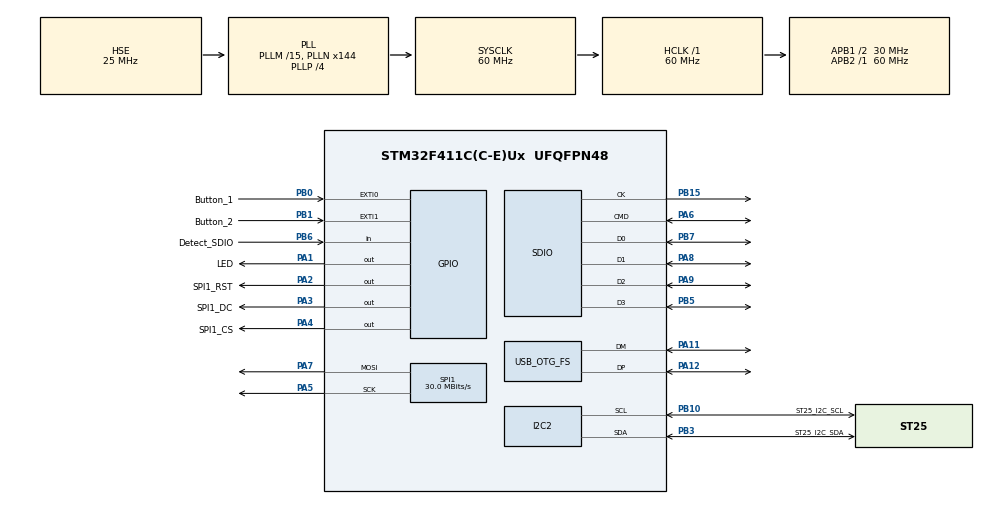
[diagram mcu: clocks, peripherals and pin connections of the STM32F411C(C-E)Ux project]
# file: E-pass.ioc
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FATFS.BSP.number=1
FATFS._CODE_PAGE=437
FATFS0.BSP.STBoard=false
FATFS0.BSP.api=Unknown
FATFS0.BSP.instance=PB6
FATFS0.BSP.ip=GPIO
FATFS0.BSP.mode=Input
FATFS0.BSP.name=Detect_SDIO
FATFS0.BSP.solution=PB6
Mcu.Family=STM32F4
Mcu.Name=STM32F411C(C-E)Ux
Mcu.Package=UFQFPN48
NVIC.EXTI0_IRQn=true\:0\:0\:false\:false\:true\:true\:true\:true
NVIC.EXTI1_IRQn=true\:0\:0\:false\:false\:true\:true\:true\:true
NVIC.OTG_FS_IRQn=true\:0\:0\:false\:false\:true\:false\:true\:true
NVIC.PriorityGroup=NVIC_PRIORITYGROUP_4
NVIC.SDIO_IRQn=true\:0\:0\:false\:false\:true\:true\:true\:true
PA1.GPIO_Label=LED
PA1.Signal=GPIO_Output
PA11.Mode=Device_Only
PA11.Signal=USB_OTG_FS_DM
PA12.Mode=Device_Only
PA12.Signal=USB_OTG_FS_DP
PA13.Mode=Serial_Wire
PA13.Signal=SYS_JTMS-SWDIO
PA14.Mode=Serial_Wire
PA14.Signal=SYS_JTCK-SWCLK
PA2.GPIO_Label=SPI1_RST
PA2.Signal=GPIO_Output
PA3.GPIO_Label=SPI1_DC
PA3.Signal=GPIO_Output
PA4.GPIO_Label=SPI1_CS
PA4.Signal=GPIO_Output
PA5.Mode=TX_Only_Simplex_Unidirect_Master
PA5.Signal=SPI1_SCK
PA6.Mode=SD_4_bits_Wide_bus
PA6.Signal=SDIO_CMD
PA7.Mode=TX_Only_Simplex_Unidirect_Master
PA7.Signal=SPI1_MOSI
PA8.Mode=SD_4_bits_Wide_bus
PA8.Signal=SDIO_D1
PA9.Mode=SD_4_bits_Wide_bus
PA9.Signal=SDIO_D2
PB0.GPIO_Label=Button_1
PB0.GPIO_ModeDefaultEXTI=GPIO_MODE_IT_FALLING
PB0.GPIO_PuPd=GPIO_PULLUP
PB0.Signal=GPXTI0
PB1.GPIO_Label=Button_2
PB1.GPIO_ModeDefaultEXTI=GPIO_MODE_IT_FALLING
PB1.GPIO_PuPd=GPIO_PULLUP
PB1.Signal=GPXTI1
PB10.GPIO_Label=ST25_I2C_SCL
PB10.Mode=I2C
PB10.Signal=I2C2_SCL
PB15.Mode=SD_4_bits_Wide_bus
PB15.Signal=SDIO_CK
PB3.GPIO_Label=ST25_I2C_SDA
PB3.Mode=I2C
PB3.Signal=I2C2_SDA
PB5.Mode=SD_4_bits_Wide_bus
PB5.Signal=SDIO_D3
PB6.GPIO_Label=Detect_SDIO
PB6.Signal=GPIO_Input
PB7.Mode=SD_4_bits_Wide_bus
PB7.Signal=SDIO_D0
PH0\ -\ OSC_IN.Mode=HSE-External-Oscillator
PH0\ -\ OSC_IN.Signal=RCC_OSC_IN
PH1\ -\ OSC_OUT.Mode=HSE-External-Oscillator
PH1\ -\ OSC_OUT.Signal=RCC_OSC_OUT
ProjectManager.HeapSize=0x200
ProjectManager.StackSize=0x400
ProjectManager.TargetToolchain=MDK-ARM V5.32
RCC.48MHZClocksFreq_Value=48000000
RCC.AHBFreq_Value=60000000
RCC.APB1CLKDivider=RCC_HCLK_DIV2
RCC.APB1Freq_Value=30000000
RCC.APB1TimFreq_Value=60000000
RCC.APB2Freq_Value=60000000
RCC.APB2TimFreq_Value=60000000
RCC.CortexFreq_Value=60000000
RCC.HCLKFreq_Value=60000000
RCC.HSE_VALUE=25000000
RCC.HSI_VALUE=16000000
RCC.LSE_VALUE=32768
RCC.PLLM=15
RCC.PLLN=144
RCC.PLLP=RCC_PLLP_DIV4
RCC.PLLQ=5
RCC.SYSCLKFreq_VALUE=60000000
RCC.SYSCLKSource=RCC_SYSCLKSOURCE_PLLCLK
RCC.VCOOutputFreq_Value=240000000
SDIO.ClockDiv=36
SPI1.CalculateBaudRate=30.0 MBits/s
SPI1.Direction=SPI_DIRECTION_2LINES
SPI1.Mode=SPI_MODE_MASTER
SPI1.VirtualType=VM_MASTER
USB_DEVICE.CLASS_NAME_FS=CDC
USB_DEVICE.VirtualMode=Cdc
USB_DEVICE.VirtualModeFS=Cdc_FS
USB_OTG_FS.VirtualMode=Device_Only
VP_FATFS_VS_SDIO.Mode=SDIO
VP_USB_DEVICE_VS_USB_DEVICE_CDC_FS.Mode=CDC_FS
board=custom

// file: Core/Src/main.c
/* USER CODE BEGIN Header */
/**
  ******************************************************************************
  * @file           : main.c
  * @brief          : Main program body
  ******************************************************************************
  * @attention
  *
  * Copyright (c) 2026 STMicroelectronics.
  * All rights reserved.
  *
  * This software is licensed under terms that can be found in the LICENSE file
  * in the root directory of this software component.
  * If no LICENSE file comes with this software, it is provided AS-IS.
  *
  ******************************************************************************
  */
/* USER CODE END Header */
#include "main.h"
#include "fatfs.h"
#include "i2c.h"
#include "sdio.h"
#include "spi.h"
#include "usb_device.h"
#include "gpio.h"

/* USER CODE BEGIN Includes */
#include "picture_transport.h"

/* USER CODE END Includes */

void SystemClock_Config(void);

int main(void)
{

  /* MCU Configuration--------------------------------------------------------*/

  /* Reset of all peripherals, Initializes the Flash interface and the Systick. */
  HAL_Init();

  /* Configure the system clock */
  SystemClock_Config();

  /* Initialize all configured peripherals */
  MX_GPIO_Init();
  MX_SDIO_SD_Init();
  MX_SPI1_Init();
  MX_USB_DEVICE_Init();
  MX_FATFS_Init();
  MX_I2C2_Init();
  /* USER CODE BEGIN 2 */
  PictureTransport_Init();

  /* USER CODE END 2 */

  /* Infinite loop */
  while (1)
  {

    /* USER CODE BEGIN 3 */
    PictureTransport_Task();

  }
  /* USER CODE END 3 */
}

void SystemClock_Config(void)
{
  RCC_OscInitTypeDef RCC_OscInitStruct = {0};
  RCC_ClkInitTypeDef RCC_ClkInitStruct = {0};

  /** Configure the main internal regulator output voltage
  */
  __HAL_RCC_PWR_CLK_ENABLE();
  __HAL_PWR_VOLTAGESCALING_CONFIG(PWR_REGULATOR_VOLTAGE_SCALE1);

  /** Initializes the RCC Oscillators according to the specified parameters
  * in the RCC_OscInitTypeDef structure.
  */
  RCC_OscInitStruct.OscillatorType = RCC_OSCILLATORTYPE_HSE;
  RCC_OscInitStruct.HSEState = RCC_HSE_ON;
  RCC_OscInitStruct.PLL.PLLState = RCC_PLL_ON;
  RCC_OscInitStruct.PLL.PLLSource = RCC_PLLSOURCE_HSE;
  RCC_OscInitStruct.PLL.PLLM = 15;
  RCC_OscInitStruct.PLL.PLLN = 144;
  RCC_OscInitStruct.PLL.PLLP = RCC_PLLP_DIV4;
  RCC_OscInitStruct.PLL.PLLQ = 5;
  if (HAL_RCC_OscConfig(&RCC_OscInitStruct) != HAL_OK)
  {
    Error_Handler();
  }

  /** Initializes the CPU, AHB and APB buses clocks
  */
  RCC_ClkInitStruct.ClockType = RCC_CLOCKTYPE_HCLK|RCC_CLOCKTYPE_SYSCLK
                              |RCC_CLOCKTYPE_PCLK1|RCC_CLOCKTYPE_PCLK2;
  RCC_ClkInitStruct.SYSCLKSource = RCC_SYSCLKSOURCE_PLLCLK;
  RCC_ClkInitStruct.AHBCLKDivider = RCC_SYSCLK_DIV1;
  RCC_ClkInitStruct.APB1CLKDivider = RCC_HCLK_DIV2;
  RCC_ClkInitStruct.APB2CLKDivider = RCC_HCLK_DIV1;

  if (HAL_RCC_ClockConfig(&RCC_ClkInitStruct, FLASH_LATENCY_1) != HAL_OK)
  {
    Error_Handler();
  }
}

void Error_Handler(void)
{
  __disable_irq();
  while (1)
  {
  }
}
